VERSION ""

NS_ :

BS_:

BU_: EECU VGT TCU SCU ABS/EBS/ESC Retarder EPS/HSCU IC DCDC BBM Display AEBS LKA ELC/ECAS HVAP VECU HCU BCM TPMS PAC ACM AVM CIOM LSCU EPB FNOx RNox ACU HCCB SCM ADCU UQS ROBD T-BOX Charge RKE DFD/DFMS LDWS FCWS BSD DCM VDR/BeiDou EMCU MCU(Axle) BMS CDC PEPS YRS Exhaust Ret. Engine Ret. AFS CCM CVG EAC SAS Tacho IVI ATC DST Camera Infotainment EHPS Gateway(INC) HOD BCA rADCU rEHPS

BO_ 2365547678 AutoDrive_ADCU: 8 ADCU
 SG_ CRC8 : 0|8@1+ (1.0,0.0) [0.0|255.0]  "" SCU,ABS/EBS/ESC,VECU,BCM,EHPS,BCA,rEHPS
 SG_ Counter : 8|4@1+ (1.0,0.0) [0.0|15.0]  "" SCU,ABS/EBS/ESC,VECU,BCM,EHPS,BCA,rEHPS
 SG_ AD Mode Enable PS : 16|2@1+ (1.0,0.0) [0.0|3.0]  "" SCU,ABS/EBS/ESC,VECU,BCM,EHPS,BCA,rEHPS
 SG_ AD Mode Engage PS : 20|2@1+ (1.0,0.0) [0.0|3.0]  "" SCU,ABS/EBS/ESC,VECU,BCM,EHPS,BCA,rEHPS

BO_ 2365553054 ADU_PSControlRequest_ADCU: 8 ADCU
 SG_ SW Angle Request PS lower byte : 0|8@1+ (0.1,0.0) [-12.8|12.7]  "deg" EHPS,rEHPS
 SG_ SW Angle Request PS upper byte : 8|8@1+ (0.1,0.0) [-12.8|12.7]  "deg" EHPS,rEHPS
 SG_ SW Angle Request Valid PS : 16|2@1+ (1.0,0.0) [0.0|3.0]  "" EHPS,rEHPS
 SG_ Message Counter : 48|8@1+ (1.0,0.0) [0.0|255.0]  "" EHPS,rEHPS
 SG_ Data Sum : 56|8@1+ (1.0,0.0) [0.0|255.0]  "" EHPS,rEHPS

BO_ 2365547740 AutoDrive_rADCU: 8 rADCU
 SG_ CRC8 : 0|8@1+ (1.0,0.0) [0.0|255.0]  "" BCA,rEHPS
 SG_ Counter : 8|4@1+ (1.0,0.0) [0.0|15.0]  "" BCA,rEHPS
 SG_ AD Mode Enable SS : 18|2@1+ (1.0,0.0) [0.0|3.0]  "" BCA,rEHPS
 SG_ AD Mode Engage SS : 22|2@1+ (1.0,0.0) [0.0|3.0]  "" BCA,rEHPS

BO_ 2365553116 ADU_SSControlRequest_rADCU: 8 rADCU
 SG_ SW Angle Request SS lower byte : 0|8@1+ (0.1,0.0) [-12.8|12.7]  "deg" rEHPS
 SG_ SW Angle Request SS upper byte : 8|8@1+ (0.1,0.0) [-12.8|12.7]  "deg" rEHPS
 SG_ SW Angle Request Valid SS : 16|2@1+ (1.0,0.0) [0.0|3.0]  "" rEHPS
 SG_ Message Counter : 48|8@1+ (1.0,0.0) [0.0|255.0]  "" rEHPS
 SG_ Data Sum : 56|8@1+ (1.0,0.0) [0.0|255.0]  "" rEHPS

BO_ 2566879965 ECUControlInformation1_rEHPS: 8 rEHPS
 SG_ Current SW Angle SS lower byte : 0|8@1+ (0.1,0.0) [-12.8|12.7]  "deg" ADCU,rADCU
 SG_ Current SW Angle SS upper byte : 8|8@1+ (0.1,0.0) [-12.8|12.7]  "" ADCU,rADCU
 SG_ Current SW Speed SS lower byte : 16|8@1+ (0.1,0.0) [-2000.0|2000.0]  "deg/s" ADCU,rADCU
 SG_ Current SW Speed SS upper byte : 24|8@1+ (0.1,0.0) [-2000.0|2000.0]  "" ADCU,rADCU
 SG_ Current SW Angle Valid SS : 32|2@1+ (1.0,0.0) [0.0|3.0]  "" ADCU,rADCU
 SG_ Current SW Speed Valid SS : 34|2@1+ (1.0,0.0) [0.0|3.0]  "" ADCU,rADCU
 SG_ Steering Error Event2 Active SS : 40|2@1+ (1.0,0.0) [0.0|3.0]  "" ADCU,rADCU
 SG_ Steering Error Event2 SS : 42|6@1+ (1.0,0.0) [0.0|63.0]  "" ADCU,rADCU
 SG_ Message Counter : 48|8@1+ (1.0,0.0) [0.0|255.0]  "" ADCU,rADCU
 SG_ Data Sum : 56|8@1+ (1.0,0.0) [0.0|255.0]  "" ADCU,rADCU

BO_ 2566880221 ECUControlInformation2_rEHPS: 8 rEHPS
 SG_ Current Driver Torque SS lower byte : 0|8@1+ (0.01,0.0) [-20.0|20.0]  "Nm" ADCU,rADCU
 SG_ Current Driver Torque SS upper byte : 8|8@1+ (0.01,0.0) [-20.0|20.0]  "" ADCU,rADCU
 SG_ Current Driver Torque Valid SS : 16|2@1+ (1.0,0.0) [0.0|3.0]  "" ADCU,rADCU
 SG_ Steering Override SS : 24|4@1+ (1.0,0.0) [0.0|15.0]  "" ADCU,rADCU
 SG_ Steering Override Valid SS : 28|4@1+ (1.0,0.0) [0.0|15.0]  "" ADCU,rADCU
 SG_ Steering System Status SS : 32|4@1+ (1.0,0.0) [0.0|15.0]  "" ADCU,rADCU
 SG_ State Voltage SS : 36|2@1+ (1.0,0.0) [0.0|3.0]  "" ADCU,rADCU
 SG_ State Temperature SS : 38|2@1+ (1.0,0.0) [0.0|3.0]  "" ADCU,rADCU
 SG_ Steering Error Event3 Active SS : 40|2@1+ (1.0,0.0) [0.0|3.0]  "" ADCU,rADCU
 SG_ Steering Error Event3 SS : 42|6@1+ (1.0,0.0) [0.0|63.0]  "" ADCU,rADCU
 SG_ Message Counter : 48|8@1+ (1.0,0.0) [0.0|255.0]  "" ADCU,rADCU
 SG_ Data Sum : 56|8@1+ (1.0,0.0) [0.0|255.0]  "" ADCU,rADCU

BO_ 2566880477 ECUControlInformation3_rEHPS: 8 rEHPS
 SG_ Steering System AD Mode State SS1 : 0|3@1+ (1.0,0.0) [0.0|7.0]  "" ADCU,rADCU
 SG_ Steering System AD Mode State SS2 : 4|3@1+ (1.0,0.0) [0.0|7.0]  "" ADCU,rADCU
 SG_ Output limitation : 7|1@1+ (1.0,0.0) [0.0|1.0]  "" ADCU,rADCU
 SG_ Current consumption : 8|8@1+ (0.2,0.0) [0.0|50.0]  "A" ADCU,rADCU
 SG_ Boost curve torque lower byte : 16|8@1+ (0.01,0.0) [-1.28|1.27]  "Nm" ADCU,rADCU
 SG_ Boost curve torque upper byte : 24|8@1+ (0.01,0.0) [-1.28|1.27]  "Nm" ADCU,rADCU
 SG_ Total torque lower byte : 32|8@1+ (0.01,0.0) [-1.28|1.27]  "Nm" ADCU,rADCU
 SG_ Total torque upper byte : 40|8@1+ (0.01,0.0) [-1.28|1.27]  "Nm" ADCU,rADCU
 SG_ Message Counter : 48|8@1+ (1.0,0.0) [0.0|255.0]  "" ADCU,rADCU
 SG_ Data Sum : 56|8@1+ (1.0,0.0) [0.0|255.0]  "" ADCU,rADCU

BO_ 2566880733 ECUControlInformation4_rEHPS: 8 rEHPS
 SG_ AHPS Failure code lower byte : 0|8@1+ (1.0,0.0) [0.0|255.0]  "" ADCU,rADCU
 SG_ AHPS Failure code upper byte : 8|8@1+ (1.0,0.0) [0.0|255.0]  "" ADCU,rADCU
 SG_ ECU Temperature SS : 16|8@1+ (1.0,0.0) [0.0|200.0]  "deg" ADCU,rADCU
 SG_ Inverter Temperature SS (estimated) : 24|8@1+ (1.0,0.0) [0.0|200.0]  "deg" ADCU,rADCU
 SG_ AHPS supply voltage SS : 32|8@1+ (0.2,0.0) [0.0|50.0]  "V" ADCU,rADCU
 SG_ AHPS torque limitation ratio SS : 40|8@1+ (1.0,0.0) [0.0|100.0]  "%" ADCU,rADCU
 SG_ Message Counter : 48|8@1+ (1.0,0.0) [0.0|255.0]  "" ADCU,rADCU
 SG_ Data Sum : 56|8@1+ (1.0,0.0) [0.0|255.0]  "" ADCU,rADCU

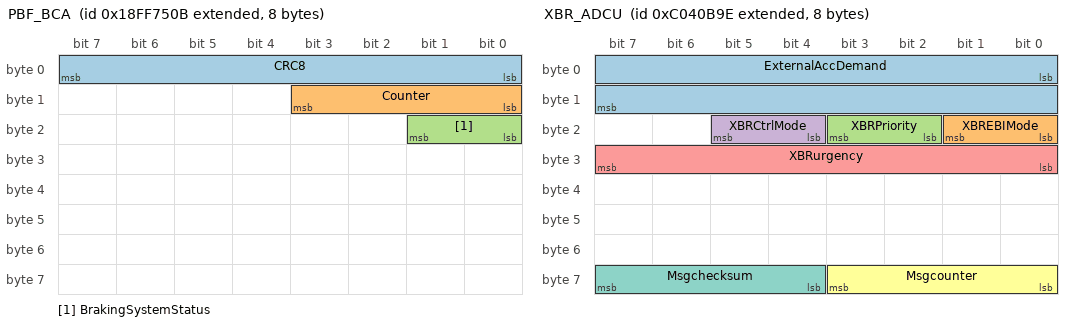
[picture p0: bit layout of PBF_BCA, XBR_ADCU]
BO_ 2566878475 PBF_BCA: 8 BCA
 SG_ CRC8 : 0|8@1+ (1.0,0.0) [0.0|255.0]  "" ADCU,rADCU
 SG_ Counter : 8|4@1+ (1.0,0.0) [0.0|15.0]  "" ADCU,rADCU
 SG_ BrakingSystemStatus : 16|2@1+ (1.0,0.0) [0.0|3.0]  "" ADCU,rADCU
 SG_ Braking System AD Mode State 1 : 24|3@1+ (1.0,0.0) [0.0|7.0]  "" ADCU,rADCU
 SG_ Braking System AD Mode State 2 : 27|3@1+ (1.0,0.0) [0.0|7.0]  "" ADCU,rADCU
 SG_ Braking Error Event Active 1 : 30|1@1+ (1.0,0.0) [0.0|1.0]  "" ADCU,rADCU
 SG_ Braking Error Event Active 2 : 31|1@1+ (1.0,0.0) [0.0|1.0]  "" ADCU,rADCU
 SG_ Braking Error Event 1 : 32|4@1+ (1.0,0.0) [0.0|15.0]  "" ADCU,rADCU
 SG_ Braking Error Event 2 : 36|4@1+ (1.0,0.0) [0.0|15.0]  "" ADCU,rADCU

BO_ 2298375691 HRW_BCA: 8 BCA

BO_ 2565865739 EBC1_BCA: 8 BCA
 SG_ ASR Engine Control Active : 0|2@1+ (1.0,0.0) [0.0|3.0]  "" VECU,BCM,ADCU,rADCU
 SG_ ASR Brake Control Active : 2|2@1+ (1.0,0.0) [0.0|3.0]  "" VECU,BCM,ADCU,rADCU
 SG_ Anti-lock braking (ABS) Active : 4|2@1+ (1.0,0.0) [0.0|3.0]  "" VECU,BCM,ADCU,rADCU
 SG_ Brake Pedal Position : 8|8@1+ (0.4,0.0) [0.0|100.0]  "%" VECU,BCM,ADCU,rADCU
 SG_ ABS Offroad Switch : 16|2@1+ (1.0,0.0) [0.0|3.0]  "" VECU,BCM,ADCU,rADCU
 SG_ ASR Offroad Switch : 18|2@1+ (1.0,0.0) [0.0|3.0]  "" VECU,BCM,ADCU,rADCU
 SG_ ASR "hill holder" Switch : 20|2@1+ (1.0,0.0) [0.0|3.0]  "" VECU,BCM,ADCU,rADCU
 SG_ Traction Control Override Switch : 22|2@1+ (1.0,0.0) [0.0|3.0]  "" VECU,BCM,ADCU,rADCU
 SG_ Accelerator Interlock Switch : 24|2@1+ (1.0,0.0) [0.0|3.0]  "" VECU,BCM,ADCU,rADCU
 SG_ Engine Derate Switch : 26|2@1+ (1.0,0.0) [0.0|3.0]  "" VECU,BCM,ADCU,rADCU
 SG_ Auxiliary Engine Shutdown Switch : 28|2@1+ (1.0,0.0) [0.0|3.0]  "" VECU,BCM,ADCU,rADCU
 SG_ Remote Accelerator Enable Switch : 30|2@1+ (1.0,0.0) [0.0|3.0]  "" VECU,BCM,ADCU,rADCU
 SG_ Engine Retarder Selection : 32|8@1+ (0.4,0.0) [0.0|100.0]  "%" VECU,BCM,ADCU,rADCU
 SG_ ABS Fully Operational : 40|2@1+ (1.0,0.0) [0.0|3.0]  "" VECU,BCM,ADCU,rADCU
 SG_ EBS Red Warning Lamp State : 42|2@1+ (1.0,0.0) [0.0|3.0]  "" VECU,BCM,ADCU,rADCU
 SG_ ABS/EBS Amber Warning State(powered vehicle) : 44|2@1+ (1.0,0.0) [0.0|3.0]  "" VECU,BCM,ADCU,rADCU
 SG_ ATC/ASR Lamp State : 46|2@1+ (1.0,0.0) [0.0|3.0]  "" VECU,BCM,ADCU,rADCU
 SG_ Source Address of Controlling Device for Brake Control : 48|8@1+ (1.0,0.0) [0.0|255.0]  "" VECU,BCM,ADCU,rADCU
 SG_ Railroad Mode Switch : 56|2@1+ (1.0,0.0) [0.0|3.0]  "" VECU,BCM,ADCU,rADCU
 SG_ Halt brake switch : 58|2@1+ (1.0,0.0) [0.0|3.0]  "" VECU,BCM,ADCU,rADCU
 SG_ Trailer ABS Status : 60|2@1+ (1.0,0.0) [0.0|3.0]  "" VECU,BCM,ADCU,rADCU
 SG_ Tractor-Mounted TABS Warning Signal : 62|2@1+ (1.0,0.0) [0.0|3.0]  "" VECU,BCM,ADCU,rADCU

BO_ 2566767627 EBC5_BCA: 8 BCA
 SG_ Brake Temperature Warning : 0|2@1+ (1.0,0.0) [0.0|3.0]  "" ADCU,rADCU
 SG_ Halt Brake Mode : 2|3@1+ (1.0,0.0) [0.0|7.0]  "" ADCU,rADCU
 SG_ Hill Holder Mode : 5|3@1+ (1.0,0.0) [0.0|7.0]  "" ADCU,rADCU
 SG_ Foundation Brake Use : 8|2@1+ (1.0,0.0) [0.0|3.0]  "" ADCU,rADCU
 SG_ XBR System State : 10|2@1+ (1.0,0.0) [0.0|3.0]  "" ADCU,rADCU
 SG_ XBR Active Control Mode : 12|4@1+ (1.0,0.0) [0.0|7.0]  "" ADCU,rADCU
 SG_ XBR Acceleration Limit : 16|8@1+ (0.1,-12.5) [-12.5|12.5]  "m/s²" ADCU,rADCU
 SG_ Parking Brake Actuator Fully Activated : 24|2@1+ (1.0,0.0) [0.0|3.0]  "" ADCU,rADCU
 SG_ Emergency Braking Active : 26|2@1+ (1.0,0.0) [0.0|3.0]  "" ADCU,rADCU
 SG_ Railroad Mode : 28|2@1+ (1.0,0.0) [0.0|3.0]  "" ADCU,rADCU

BO_ 2349075358 XBR_ADCU: 8 ADCU
 SG_ ExternalAccDemand : 0|16@1+ (0.0004883,-15.687) [-15.687|15.687]  "m/s²" ABS/EBS/ESC,VECU,BCM,BCA
 SG_ XBREBIMode : 16|2@1+ (1.0,0.0) [0.0|3.0]  "" ABS/EBS/ESC,VECU,BCM,BCA
 SG_ XBRPriority : 18|2@1+ (1.0,0.0) [0.0|3.0]  "" ABS/EBS/ESC,VECU,BCM,BCA
 SG_ XBRCtrlMode : 20|2@1+ (1.0,0.0) [0.0|3.0]  "" ABS/EBS/ESC,VECU,BCM,BCA
 SG_ XBRurgency : 24|8@1+ (0.4,0.0) [0.0|100.0]  "%" ABS/EBS/ESC,VECU,BCM,BCA
 SG_ Msgcounter : 56|4@1+ (1.0,0.0) [0.0|15.0]  "count" ABS/EBS/ESC,VECU,BCM,BCA
 SG_ Msgchecksum : 60|4@1+ (1.0,0.0) [0.0|15.0]  "count" ABS/EBS/ESC,VECU,BCM,BCA

BO_ 2566878878 Warning_EBS_ADCU: 8 ADCU
 SG_ Brake Temp Warning PS : 0|2@1+ (1.0,0.0) [0.0|3.0]  "" ABS/EBS/ESC,BCA
 SG_ Brake Pressure Warning PS : 4|2@1+ (1.0,0.0) [0.0|3.0]  "" ABS/EBS/ESC,BCA

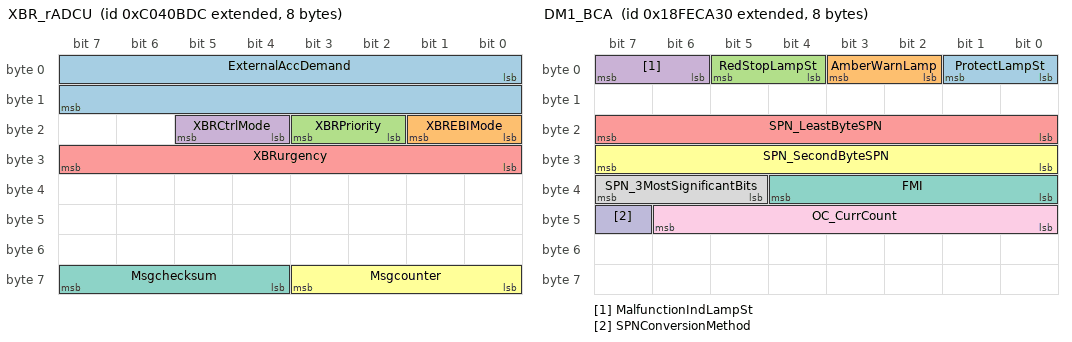
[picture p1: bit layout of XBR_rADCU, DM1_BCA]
BO_ 2349075420 XBR_rADCU: 8 rADCU
 SG_ ExternalAccDemand : 0|16@1+ (0.0004883,-15.687) [-15.687|15.687]  "m/s²" VECU,BCM,BCA
 SG_ XBREBIMode : 16|2@1+ (1.0,0.0) [0.0|3.0]  "" VECU,BCM,BCA
 SG_ XBRPriority : 18|2@1+ (1.0,0.0) [0.0|3.0]  "" VECU,BCM,BCA
 SG_ XBRCtrlMode : 20|2@1+ (1.0,0.0) [0.0|3.0]  "" VECU,BCM,BCA
 SG_ XBRurgency : 24|8@1+ (0.4,0.0) [0.0|100.0]  "%" VECU,BCM,BCA
 SG_ Msgcounter : 56|4@1+ (1.0,0.0) [0.0|15.0]  "count" VECU,BCM,BCA
 SG_ Msgchecksum : 60|4@1+ (1.0,0.0) [0.0|15.0]  "count" VECU,BCM,BCA

BO_ 2566878940 Warning_EBS_rADCU: 8 rADCU
 SG_ Brake Temp Warning SS : 2|2@1+ (1.0,0.0) [0.0|3.0]  "" BCA
 SG_ Brake Pressure Warning SS : 6|2@1+ (1.0,0.0) [0.0|3.0]  "" BCA

BO_ 2566834736 DM1_BCA: 8 BCA
 SG_ ProtectLampSt  : 0|2@1+ (1.0,0.0) [0.0|3.0]  "" ADCU,rADCU
 SG_ AmberWarnLamp  : 2|2@1+ (1.0,0.0) [0.0|3.0]  "" ADCU,rADCU
 SG_ RedStopLampSt  : 4|2@1+ (1.0,0.0) [0.0|3.0]  "" ADCU,rADCU
 SG_ MalfunctionIndLampSt : 6|2@1+ (1.0,0.0) [0.0|3.0]  "" ADCU,rADCU
 SG_ SPN_LeastByteSPN : 16|8@1+ (1.0,0.0) [0.0|255.0]  "" ADCU,rADCU
 SG_ SPN_SecondByteSPN : 24|8@1+ (1.0,0.0) [0.0|255.0]  "" ADCU,rADCU
 SG_ FMI : 32|5@1+ (1.0,0.0) [0.0|31.0]  "" ADCU,rADCU
 SG_ SPN_3MostSignificantBits : 37|3@1+ (1.0,0.0) [0.0|7.0]  "" ADCU,rADCU
 SG_ OC_CurrCount : 40|7@1+ (1.0,0.0) [0.0|127.0]  "" ADCU,rADCU
 SG_ SPNConversionMethod : 47|1@1+ (1.0,0.0) [0.0|1.0]  "" ADCU,rADCU

CM_ " ";
CM_ SG_ 2365547678 CRC8 "校验";
CM_ SG_ 2365547678 Counter "计数";
CM_ SG_ 2365547678 AD Mode Enable PS "允许进入自动驾驶模式(ADU_PS)";
CM_ SG_ 2365547678 AD Mode Engage PS "请求进入自动驾驶模式(ADU_PS)";
CM_ SG_ 2365547740 CRC8 "校验";
CM_ SG_ 2365547740 Counter "计数";
CM_ SG_ 2365547740 AD Mode Enable SS "允许进入自动驾驶模式(ADU_SS)";
CM_ SG_ 2365547740 AD Mode Engage SS "请求进入自动驾驶模式(ADU_SS)";
CM_ SG_ 2566878475 CRC8 "校验";
CM_ SG_ 2566878475 Counter "计数";
CM_ SG_ 2566878475 BrakingSystemStatus "制动系统当前状态(备份系统)";
CM_ SG_ 2566878475 Braking System AD Mode State 1 "BCA受ADCU控制状态反馈接口";
CM_ SG_ 2566878475 Braking System AD Mode State 2 "BCA受rADCU控制状态反馈接口";
CM_ SG_ 2566878475 Braking Error Event Active 1 "制动发生错误事件1（主系统）";
CM_ SG_ 2566878475 Braking Error Event Active 2 "制动发生错误事件2(备份系统)";
CM_ SG_ 2566878475 Braking Error Event 1 "制动发生错误事件1列表(主系统)";
CM_ SG_ 2566878475 Braking Error Event 2 "制动发生错误事件2列表(备份系统)";
CM_ SG_ 2298375691 Front Axle Left Wheel Speed "High resolution measurement of the speed of the left wheel of the steer axle.";
CM_ SG_ 2298375691 Front Axle Right Wheel Speed "High Resolution measurement of the speed of the right wheel of the steer axle.";
CM_ SG_ 2298375691 Rear Axle Left Wheel Speed "High Resolution measurement of the speed of the left wheel of the rear axle.";
CM_ SG_ 2298375691 Rear Axle Right Wheel Speed "High Resolution measurement of the speed of the right wheel of the rear axle.";
CM_ SG_ 2565865739 Anti-lock braking (ABS) Active "ABS当前激活状态(主系统)";
CM_ SG_ 2565865739 EBS brake switch "制动踏板开关(主系统)";
CM_ SG_ 2565865739 Brake Pedal Position "制动踏板位置(主系统)";
CM_ SG_ 2566878878 Brake Temp Warning PS "制动系统过热警告(主系统)";
CM_ SG_ 2566878878 Brake Pressure Warning PS "制动系统气压警告(主系统)";
CM_ SG_ 2566878940 Brake Temp Warning SS "制动系统过热警告(备份系统)";
CM_ SG_ 2566878940 Brake Pressure Warning SS "制动系统气压警告(备份系统)";

    BA_DEF_ BO_  "GenMsgSendType" ENUM  "cyclic","Event","IfActive","OnRequest","CA","CE","NoMsgSendType";
    BA_DEF_ BO_  "GenMsgCycleTime" INT 0 0;
    BA_DEF_ SG_  "GenSigSendType" ENUM  "cyclic","OnChange","OnWrite","IfActive","OnChangeWithRepetition","OnWriteWithRepetition","IfActiveWithRepetition","NoSigSendType","OnChangeAndIfActive","OnChangeAndIfActiveWithRepetition","CA", "CE","Event";
    BA_DEF_  "DBName" STRING ;
    BA_DEF_ SG_  "SPN" INT 0 0;
    BA_DEF_  "NMIdType" ENUM  "0: standard (11 bit, default)","1: extended (29 bit)";
    BA_DEF_  "NmMessageCount" INT 0 256;
    BA_DEF_ SG_  "GenSigEVName" STRING ;
    BA_DEF_ SG_  "GenSigILSupport" ENUM  "Yes","No";
    BA_DEF_ BO_  "GenMsgILSupport" ENUM  "Yes","No";
    BA_DEF_ BO_  "GenMsgRequestable" INT 0 1;
    BA_DEF_ BO_  "VFrameFormat" ENUM  "StandardCAN","ExtendedCAN","reserved","J1939PG";
    BA_DEF_ BU_  "NodeLayerModules" STRING ;
    BA_DEF_ BU_  "NmStationAddress" INT 0 255;
    BA_DEF_  "BusType" STRING ;

    BA_DEF_DEF_  "GenMsgSendType" "cyclic";
    BA_DEF_DEF_  "GenMsgCycleTime" 0;
    BA_DEF_DEF_  "GenSigSendType" "cyclic";

    BA_DEF_DEF_  "DBName" "";
    BA_DEF_DEF_  "SPN" 0;
    BA_DEF_DEF_  "NMIdType" "0: standard (11 bit, default)";
    BA_DEF_DEF_  "NmMessageCount" 128;
    BA_DEF_DEF_  "GenSigEVName" "Env@Nodename_@Signame";
    BA_DEF_DEF_  "GenSigILSupport" "Yes";
    BA_DEF_DEF_  "GenMsgILSupport" "Yes";
    BA_DEF_DEF_  "GenMsgRequestable" 1;
    BA_DEF_DEF_  "VFrameFormat" "J1939PG";
    BA_DEF_DEF_  "NodeLayerModules" "oseknm01.dll,CANoeILNLVector.dll,J1939_IL.dll";
    BA_DEF_DEF_  "NmStationAddress" 254;
    BA_DEF_DEF_  "BusType" "";
BA_ "DBName" "通讯矩阵- 赢彻B1-I-CAN0724";
    BA_ "BusType" "J1939";
BA_ "GenMsgCycleTime"BO_ 2365547678 100;
BA_ "GenMsgCycleTime"BO_ 2365553054 20;
BA_ "GenMsgCycleTime"BO_ 2365547740 100;
BA_ "GenMsgCycleTime"BO_ 2365553116 20;
BA_ "GenMsgCycleTime"BO_ 2566879965 20;
BA_ "GenMsgCycleTime"BO_ 2566880221 20;
BA_ "GenMsgCycleTime"BO_ 2566880477 20;
BA_ "GenMsgCycleTime"BO_ 2566880733 20;
BA_ "GenMsgCycleTime"BO_ 2566878475 100;
BA_ "GenMsgCycleTime"BO_ 2298375691 20;
BA_ "SPN" SG_ 2298375691 Front Axle Left Wheel Speed 1592;
BA_ "SPN" SG_ 2298375691 Front Axle Right Wheel Speed 1593;
BA_ "SPN" SG_ 2298375691 Rear Axle Left Wheel Speed 1594;
BA_ "SPN" SG_ 2298375691 Rear Axle Right Wheel Speed 1595;
BA_ "GenMsgCycleTime"BO_ 2565865739 100;
BA_ "SPN" SG_ 2565865739 ASR Engine Control Active 561;
BA_ "SPN" SG_ 2565865739 ASR Brake Control Active 562;
BA_ "SPN" SG_ 2565865739 Anti-lock braking (ABS) Active 563;
BA_ "SPN" SG_ 2565865739 EBS brake switch 1121;
BA_ "SPN" SG_ 2565865739 Brake Pedal Position 521;
BA_ "SPN" SG_ 2565865739 ABS Offroad Switch 575;
BA_ "SPN" SG_ 2565865739 ASR Offroad Switch 576;
BA_ "SPN" SG_ 2565865739 ASR "hill holder" Switch 577;
BA_ "SPN" SG_ 2565865739 Traction Control Override Switch 1238;
BA_ "SPN" SG_ 2565865739 Accelerator Interlock Switch 972;
BA_ "SPN" SG_ 2565865739 Engine Derate Switch 971;
BA_ "SPN" SG_ 2565865739 Auxiliary Engine Shutdown Switch 970;
BA_ "SPN" SG_ 2565865739 Remote Accelerator Enable Switch 969;
BA_ "SPN" SG_ 2565865739 Engine Retarder Selection 973;
BA_ "SPN" SG_ 2565865739 ABS Fully Operational 1243;
BA_ "SPN" SG_ 2565865739 EBS Red Warning Lamp State 1439;
BA_ "SPN" SG_ 2565865739 ABS/EBS Amber Warning State(powered vehicle) 1438;
BA_ "SPN" SG_ 2565865739 ATC/ASR Lamp State 1793;
BA_ "SPN" SG_ 2565865739 Source Address of Controlling Device for Brake Control 1481;
BA_ "SPN" SG_ 2565865739 Railroad Mode Switch 7941;
BA_ "SPN" SG_ 2565865739 Halt brake switch 2911;
BA_ "SPN" SG_ 2565865739 Trailer ABS Status 1836;
BA_ "SPN" SG_ 2565865739 Tractor-Mounted TABS Warning Signal 1792;
BA_ "GenMsgCycleTime"BO_ 2566767627 100;
BA_ "SPN" SG_ 2566767627 Brake Temperature Warning 3839;
BA_ "SPN" SG_ 2566767627 Halt Brake Mode 2913;
BA_ "SPN" SG_ 2566767627 Hill Holder Mode 2912;
BA_ "SPN" SG_ 2566767627 Foundation Brake Use 2919;
BA_ "SPN" SG_ 2566767627 XBR System State 2917;
BA_ "SPN" SG_ 2566767627 XBR Active Control Mode 2918;
BA_ "SPN" SG_ 2566767627 XBR Acceleration Limit 2921;
BA_ "SPN" SG_ 2566767627 Parking Brake Actuator Fully Activated 5275;
BA_ "SPN" SG_ 2566767627 Emergency Braking Active 5847;
BA_ "SPN" SG_ 2566767627 Railroad Mode 7942;
BA_ "GenMsgCycleTime"BO_ 2349075358 20;
BA_ "SPN" SG_ 2349075358 ExternalAccDemand 2920;
BA_ "SPN" SG_ 2349075358 XBREBIMode 2914;
BA_ "SPN" SG_ 2349075358 XBRPriority 2915;
BA_ "SPN" SG_ 2349075358 XBRCtrlMode 2916;
BA_ "SPN" SG_ 2349075358 XBRurgency 4099;
BA_ "SPN" SG_ 2349075358 Msgcounter 3189;
BA_ "SPN" SG_ 2349075358 Msgchecksum 3188;
BA_ "GenMsgCycleTime"BO_ 2566878878 100;
BA_ "GenMsgCycleTime"BO_ 2349075420 20;
BA_ "SPN" SG_ 2349075420 ExternalAccDemand 2920;
BA_ "SPN" SG_ 2349075420 XBREBIMode 2914;
BA_ "SPN" SG_ 2349075420 XBRPriority 2915;
BA_ "SPN" SG_ 2349075420 XBRCtrlMode 2916;
BA_ "SPN" SG_ 2349075420 XBRurgency 4099;
BA_ "SPN" SG_ 2349075420 Msgcounter 3189;
BA_ "SPN" SG_ 2349075420 Msgchecksum 3188;
BA_ "GenMsgCycleTime"BO_ 2566878940 100;
BA_ "GenMsgCycleTime"BO_ 2566834736 1000;
BA_ "SPN" SG_ 2566834736 ProtectLampSt  987;
BA_ "SPN" SG_ 2566834736 AmberWarnLamp  624;
BA_ "SPN" SG_ 2566834736 RedStopLampSt  623;
BA_ "SPN" SG_ 2566834736 MalfunctionIndLampSt 1213;
BA_ "SPN" SG_ 2566834736 SPN_LeastByteSPN 1214;
BA_ "SPN" SG_ 2566834736 SPN_SecondByteSPN 1214;
BA_ "SPN" SG_ 2566834736 FMI 1215;
BA_ "SPN" SG_ 2566834736 SPN_3MostSignificantBits 1214;
BA_ "SPN" SG_ 2566834736 OC_CurrCount 1216;
BA_ "SPN" SG_ 2566834736 SPNConversionMethod 1706;

VAL_ 2365547678 AD Mode Enable PS 0 "inhabit" 1 "enable" 2 "fail" 3 "reserve" ;
VAL_ 2365547678 AD Mode Engage PS 0 "inhabit" 1 "engage" 2 "reserve" 3 "reserve" ;
VAL_ 2365553054 SW Angle Request Valid PS 0 "Valid" 1 "Invalid" ;
VAL_ 2365547740 AD Mode Enable SS 0 "inhabit" 1 "enable" 2 "fail" 3 "reserve" ;
VAL_ 2365547740 AD Mode Engage SS 0 "inhabit" 1 "engage" 2 "reserve" 3 "reserve" ;
VAL_ 2365553116 SW Angle Request Valid SS 0 "Valid" 1 "Invalid" ;
VAL_ 2566879965 Current SW Angle Valid SS 0 "Valid" 1 "Invalid" ;
VAL_ 2566879965 Current SW Speed Valid SS 0 "Valid" 1 "Invalid" ;
VAL_ 2566879965 Steering Error Event2 Active SS 0 "Inactive" 1 "Active" ;
VAL_ 2566880221 Current Driver Torque Valid SS 0 "Valid" 1 "Invalid" ;
VAL_ 2566880221 Steering Override SS 0 "Inactive" 1 "Active" 2 "DriverReaction" ;
VAL_ 2566880221 Steering Override Valid SS 0 "Valid" 1 "Invalid" ;
VAL_ 2566880221 Steering System Status SS 0 "Normal" 1 "NoElectricalAssistance" 2 "HydraulicFailure(NotapplicableatB0sample)" 3 "Fault" 4 "Reserve" ;
VAL_ 2566880221 State Voltage SS 0 "Normal" 1 "OverVoltage" 2 "UnderVoltage" ;
VAL_ 2566880221 State Temperature SS 0 "Normal" 1 "OverHeat" ;
VAL_ 2566880221 Steering Error Event3 Active SS 0 "Inactive" 1 "Active" ;
VAL_ 2566880477 Steering System AD Mode State SS1 0 "NotReadySS1" 1 "ReadySS1" 2 "StandbySS1" 3 "ADUEngagedSS1" 4 "Reserve" 5 "ErrorSS1" ;
VAL_ 2566880477 Steering System AD Mode State SS2 0 "NotReadySS2" 1 "ReadySS2" 2 "StandbySS2" 3 "ADUEngagedSS2" 4 "Reserve" 5 "ErrorSS2" ;
VAL_ 2566878475 BrakingSystemStatus 0 "Normal" 1 "Fault" 2 "Reserve" 3 "Reserve" ;
VAL_ 2566878475 Braking System AD Mode State 1 0 "NotReadySS1" 1 "ReadySS1" 2 "StandbySS1" 3 "ADUEngagedSS1" 4 "Reserve" 5 "ErrorSS1" ;
VAL_ 2566878475 Braking System AD Mode State 2 0 "NotReadySS2" 1 "ReadySS2" 2 "StandbySS2" 3 "ADUEngagedSS2" 4 "Reserve" 5 "ErrorSS2" ;
VAL_ 2566878475 Braking Error Event Active 1 0 "Inactive" 1 "Active" ;
VAL_ 2566878475 Braking Error Event Active 2 0 "Inactive" 1 "Active" ;
VAL_ 2566878475 Braking Error Event 1 0 "ADUPS故障" 1 "ADModeEnablePS丢失" 2 "ADModeEngagePS丢失" 3 "XBRRequestADUPS丢失" 4 "ADUSS故障" 5 "ADModeEnableSS丢失" 6 "ADModeEngageSS丢失" 7 "XBRRequestADUPS丢失" ;
VAL_ 2566878475 Braking Error Event 2 0 "ADUPS故障" 1 "ADModeEnablePS丢失" 2 "ADModeEngagePS丢失" 3 "XBRRequestADUPS丢失" 4 "ADUSS故障" 5 "ADModeEnableSS丢失" 6 "ADModeEngageSS丢失" 7 "XBRRequestADUPS丢失" ;
VAL_ 2565865739 ASR Brake Control Active 0 "ATCbrakecontrolpassive" 1 "ATCbrakecontrolactive" 2 "ATCbrakecontrolnotinstalled" ;
VAL_ 2565865739 Anti-lock braking (ABS) Active 0 "ATCenginecontrolpassive" 1 "ATCenginecontrolactive" 2 "ATCenginecontrolnotinstalled" ;
VAL_ 2565865739 EBS brake switch 0 "Brakepedalisnotbeingpressed" 1 "Brakepedalisbeingpressed" 2 "Errorindicator" 3 "Notavailableornotinstalled" ;
VAL_ 2565865739 ABS Offroad Switch 0 "ABSoff-roadswitchpassive" 1 "ABSoff-roadswitchactive" ;
VAL_ 2565865739 ASR Offroad Switch 0 "ATCoff-roadswitchpassive" 1 "ATCoff-roadswitchactive" ;
VAL_ 2565865739 ASR "hill holder" Switch 0 "hillholderswitchpassive" 1 "hillholderswitchactive" 2 "Errorindicator" 3 "notavailable(HSAnotconfigured)" ;
VAL_ 2565865739 Traction Control Override Switch 0 "Off" 1 "On" 2 "Error" 3 "Notavailableornotinstalled" ;
VAL_ 2565865739 Accelerator Interlock Switch 0 "Off" 1 "On" 2 "Error" 3 "Notavailable" ;
VAL_ 2565865739 Engine Derate Switch 0 "Off" 1 "On" 2 "Error" 3 "Notavailable" ;
VAL_ 2565865739 Auxiliary Engine Shutdown Switch 0 "Off" 1 "On" 2 "Error" 3 "Notavailable" ;
VAL_ 2565865739 Remote Accelerator Enable Switch 0 "Off" 1 "On" 2 "Error" 3 "Notavailable" ;
VAL_ 2565865739 EBS Red Warning Lamp State 0 "EBSredwarninglampoff" 1 "EBSredwarninglampon" 2 "EBSredwarninglampnotsupported(noEBD)" ;
VAL_ 2565865739 ABS/EBS Amber Warning State(powered vehicle) 0 "ABSlampoff" 1 "ABSlampon" ;
VAL_ 2565865739 ATC/ASR Lamp State 0 "ATClampoff" 1 "ATClampon" ;
VAL_ 2566767627 Brake Temperature Warning 0 "NotActive" 1 "Active" 2 "Reserved" 3 "notavailable" ;
VAL_ 2566767627 Foundation Brake Use 0 "Foundationbrakesnotinuse" 1 "Foundationbrakesinuse" 2 "Reserved" 3 "Notavailable" ;
VAL_ 2566767627 Emergency Braking Active 0 "HybridSystemStopIndicatorisoff" 1 "HybridSystemStopIndicatorisoncontinuously" 2 "HybridSystemStopIndicatorisflashing" 3 "Notavailable" ;
VAL_ 2349075358 XBREBIMode 0 "NoEnduranceBrakeIntegrationallowed" 1 "OnlyEnduranceBrakesallowed" 2 "EnduranceBrakeIntegrationallowed" 3 "Notdefined" ;
VAL_ 2349075358 XBRPriority 0 "Highestpriority" 1 "Highpriority" 2 "Mediumpriority" 3 "Lowpriority" ;
VAL_ 2349075358 XBRCtrlMode 0 "Overridedisabled" 1 "Accelerationcontrolwithadditionmode" 2 "Accelerationcontrolwithmaximummode" 3 "Notdefined" ;
VAL_ 2566878878 Brake Temp Warning PS 0 "Inactive" 1 "Active" ;
VAL_ 2566878878 Brake Pressure Warning PS 0 "Inactive" 1 "Active" ;
VAL_ 2349075420 XBREBIMode 0 "NoEnduranceBrakeIntegrationallowed" 1 "OnlyEnduranceBrakesallowed" 2 "EnduranceBrakeIntegrationallowed" 3 "Notdefined" ;
VAL_ 2349075420 XBRPriority 0 "Highestpriority" 1 "Highpriority" 2 "Mediumpriority" 3 "Lowpriority" ;
VAL_ 2349075420 XBRCtrlMode 0 "Overridedisabled" 1 "Accelerationcontrolwithadditionmode" 2 "Accelerationcontrolwithmaximummode" 3 "Notdefined" ;
VAL_ 2566878940 Brake Temp Warning SS 0 "Inactive" 1 "Active" ;
VAL_ 2566878940 Brake Pressure Warning SS 0 "Inactive" 1 "Active" ;
VAL_ 2566834736 ProtectLampSt  0 "LampOff" 1 "LampOn" ;
VAL_ 2566834736 AmberWarnLamp  0 "LampOff" 1 "LampOn" ;
VAL_ 2566834736 RedStopLampSt  0 "LampOff" 1 "LampOn" ;
VAL_ 2566834736 MalfunctionIndLampSt 0 "LampOff" 1 "LampOn" ;
